# CY8C4248AZI_L475 register map
File version: 0.1
PSoC 4200L
Registers are 32-bit, read-write, no defined reset value unless marked. A register's access mark holds for its fields unless they carry their own. Offsets are from the block's base; lines under a group give offsets from that group; [hi:lo] are bit positions; {n}, {i} and the like mark numbered series; 'fields as' and 'values as' point back to an identical list; <NAME> marks a mode.

## Memory map
0x00000000 IDAC0 — IDAC
0x00000000 IDAC3 — IDAC
0x00000000 IDAC2 — IDAC
0x00000000 IDAC1 — IDAC
0x00000000 M1PWM
0x00000000 M0PWM
0x00000000 QD2
0x00000000 QD1
0x00000000 QD0
0x00000000 QD4
0x00000000 M2PWM
0x00000000 SRV4
0x00000000 SRV3
0x00000000 UART — Serial Communication Block
0x00000000 ADC — Sequencing SAR ADC
0x00000000 SRV2
0x00000000 M3PWM
0x00000000 USBFS
0x00000000 SRV1
0x40101000 DMAC — DMAC Registers

## IDAC0 — IDAC
Base 0x00000000
Same registers: IDAC3 0x00000000
0x40280004 CSD_IDAC_POLARITY
0x40280008 CSD_IDAC
0x4028FF00 CSD_TRIM1 — CSD IDAC TRIM1
0x4028FF04 CSD_TRIM2 — CSD IDAC TRIM2

## IDAC2 — IDAC
Base 0x00000000
Same registers: IDAC1 0x00000000
0x40290004 CSD_IDAC_POLARITY
0x40290008 CSD_IDAC
0x4029FF00 CSD_TRIM1 — CSD IDAC TRIM1
0x4029FF04 CSD_TRIM2 — CSD IDAC TRIM2

## M1PWM
Base 0x00000000
0x40200248 COUNTER — Current counter value
0x4020024C CC — Compare / capture value
0x40200250 CC_BUF — Compare / capture buffer value
0x40200254 PERIOD — Period value
0x40200258 PERIOD_BUF — Period buffer value

## M0PWM
Base 0x00000000
0x40200148 COUNTER — Current counter value
0x4020014C CC — Compare / capture value
0x40200150 CC_BUF — Compare / capture buffer value
0x40200154 PERIOD — Period value
0x40200158 PERIOD_BUF — Period buffer value

## QD2
Base 0x00000000
0x40200108 COUNTER — Current counter value
0x4020010C CC — Compare / capture value
0x40200110 CC_BUF — Compare / capture buffer value
0x40200114 PERIOD — Period value
0x40200118 PERIOD_BUF — Period buffer value

## QD1
Base 0x00000000
0x402002C8 COUNTER — Current counter value
0x402002CC CC — Compare / capture value
0x402002D0 CC_BUF — Compare / capture buffer value
0x402002D4 PERIOD — Period value
0x402002D8 PERIOD_BUF — Period buffer value

## QD0
Base 0x00000000
0x40200188 COUNTER — Current counter value
0x4020018C CC — Compare / capture value
0x40200190 CC_BUF — Compare / capture buffer value
0x40200194 PERIOD — Period value
0x40200198 PERIOD_BUF — Period buffer value

## QD4
Base 0x00000000
0x40200288 COUNTER — Current counter value
0x4020028C CC — Compare / capture value
0x40200290 CC_BUF — Compare / capture buffer value
0x40200294 PERIOD — Period value
0x40200298 PERIOD_BUF — Period buffer value

## M2PWM
Base 0x00000000
0x40200208 COUNTER — Current counter value
0x4020020C CC — Compare / capture value
0x40200210 CC_BUF — Compare / capture buffer value
0x40200214 PERIOD — Period value
0x40200218 PERIOD_BUF — Period buffer value

## SRV4
Base 0x00000000
0x400F0024 SRV4_COMPARE_1 16-bit — UDB.D0 - Assigned Compare1 Value
0x400F0034 SRV4_COMPARE_2 16-bit — UDB.D1 - Assigned Compare2 Value
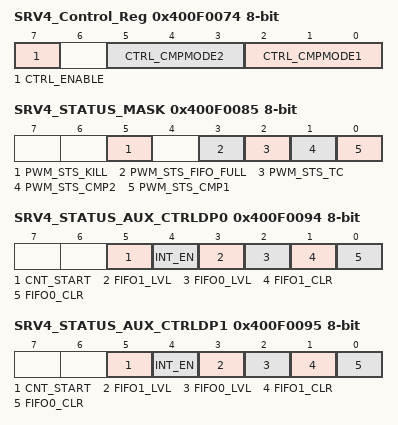
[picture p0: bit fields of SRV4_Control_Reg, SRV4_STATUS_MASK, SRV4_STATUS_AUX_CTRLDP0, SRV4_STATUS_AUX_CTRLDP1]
0x400F0074 SRV4_Control_Reg 8-bit — UDB Control Register - Assigned Control Register Value
  [7] CTRL_ENABLE — Enable the PWM
  [5:3] CTRL_CMPMODE2 — Compare mode 2
  [2:0] CTRL_CMPMODE1 — Compare mode 1
0x400F0085 SRV4_STATUS_MASK 8-bit — UDB Status bits Interrupt Mask Enable Register
  [5] PWM_STS_KILL ro — Enables the Interrupt on Kill
  [3] PWM_STS_FIFO_FULL ro — FIFO Full Status Mask
  [2] PWM_STS_TC ro — Enables the Interrupt on Terminal Count
  [1] PWM_STS_CMP2 ro — Enables the Interrupt on Compare 2
  [0] PWM_STS_CMP1 ro — Enables the Interrupt on Compare 1
0x400F0094 SRV4_STATUS_AUX_CTRLDP0 8-bit — UDB Auxilliary Control Register
  [5] CNT_START — FIFO0 clear
    0=E_CNT_START0 (Disable counter); 1=E_CNT_START1 (Enable counter)
  [4] INT_EN
    0=E_INT_EN0 (Interrupt disabled); 1=E_INT_EN1 (Interrupt enabled)
  [3] FIFO1_LVL — FIFO level
    0=E_FIFO_LVL_0 (FIFO LVL: input mode: FIFO not full; output mode: FIFO not empty); 1=E_FIFO_LVL_1 (FIFO LVL: input mode: FIFO at least 1/2 empty; output mode: FIFO at least 1/2 full)
  [2] FIFO0_LVL — FIFO level
    values as FIFO1_LVL
  [1] FIFO1_CLR — FIFO1 clear
    0=E_FIFO_CLR_0 (Normal FIFO operation); 1=E_FIFO_CLR_1 (Clear FIFO state)
  [0] FIFO0_CLR — FIFO0 clear
    values as FIFO1_CLR
0x400F0095 SRV4_STATUS_AUX_CTRLDP1 8-bit — UDB Auxilliary Control Register
  fields as SRV4_STATUS_AUX_CTRLDP0
